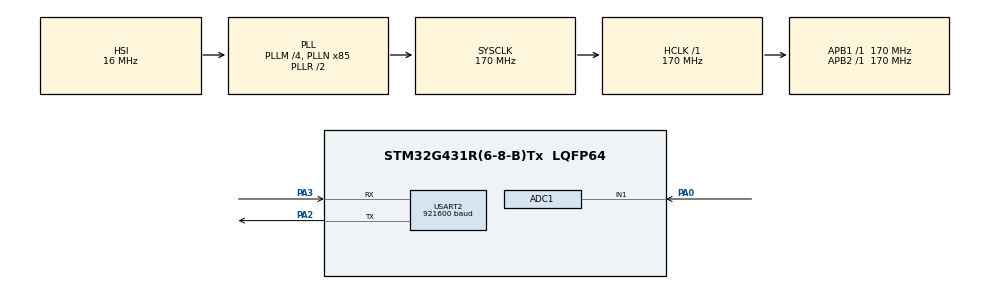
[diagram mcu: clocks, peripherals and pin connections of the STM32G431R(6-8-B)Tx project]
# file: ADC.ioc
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ADC1.Channel-0\#ChannelRegularConversion=ADC_CHANNEL_1
ADC1.ExternalTrigConv=ADC_EXTERNALTRIG_T2_TRGO
ADC1.NbrOfConversionFlag=1
ADC1.OffsetNumber-0\#ChannelRegularConversion=ADC_OFFSET_NONE
ADC1.Overrun=ADC_OVR_DATA_OVERWRITTEN
ADC1.Rank-0\#ChannelRegularConversion=1
ADC1.SamplingTime-0\#ChannelRegularConversion=ADC_SAMPLETIME_47CYCLES_5
ADC1.master=1
Dma.ADC1.1.Direction=DMA_PERIPH_TO_MEMORY
Dma.ADC1.1.EventEnable=DISABLE
Dma.ADC1.1.Instance=DMA1_Channel2
Dma.ADC1.1.MemDataAlignment=DMA_MDATAALIGN_HALFWORD
Dma.ADC1.1.MemInc=DMA_MINC_ENABLE
Dma.ADC1.1.Mode=DMA_CIRCULAR
Dma.ADC1.1.PeriphDataAlignment=DMA_PDATAALIGN_HALFWORD
Dma.ADC1.1.PeriphInc=DMA_PINC_DISABLE
Dma.ADC1.1.Polarity=HAL_DMAMUX_REQ_GEN_RISING
Dma.ADC1.1.Priority=DMA_PRIORITY_LOW
Dma.ADC1.1.RequestNumber=1
Dma.ADC1.1.SignalID=NONE
Dma.ADC1.1.SyncEnable=DISABLE
Dma.ADC1.1.SyncPolarity=HAL_DMAMUX_SYNC_NO_EVENT
Dma.ADC1.1.SyncRequestNumber=1
Dma.ADC1.1.SyncSignalID=NONE
Dma.Request0=USART2_TX
Dma.Request1=ADC1
Dma.USART2_TX.0.Direction=DMA_MEMORY_TO_PERIPH
Dma.USART2_TX.0.EventEnable=DISABLE
Dma.USART2_TX.0.Instance=DMA1_Channel1
Dma.USART2_TX.0.MemDataAlignment=DMA_MDATAALIGN_BYTE
Dma.USART2_TX.0.MemInc=DMA_MINC_ENABLE
Dma.USART2_TX.0.Mode=DMA_NORMAL
Dma.USART2_TX.0.PeriphDataAlignment=DMA_PDATAALIGN_BYTE
Dma.USART2_TX.0.PeriphInc=DMA_PINC_DISABLE
Dma.USART2_TX.0.Polarity=HAL_DMAMUX_REQ_GEN_RISING
Dma.USART2_TX.0.Priority=DMA_PRIORITY_LOW
Dma.USART2_TX.0.RequestNumber=1
Dma.USART2_TX.0.SignalID=NONE
Dma.USART2_TX.0.SyncEnable=DISABLE
Dma.USART2_TX.0.SyncPolarity=HAL_DMAMUX_SYNC_NO_EVENT
Dma.USART2_TX.0.SyncRequestNumber=1
Dma.USART2_TX.0.SyncSignalID=NONE
Mcu.Family=STM32G4
Mcu.Name=STM32G431R(6-8-B)Tx
Mcu.Package=LQFP64
NVIC.ADC1_2_IRQn=true\:0\:0\:false\:false\:true\:true\:true\:true
NVIC.DMA1_Channel1_IRQn=true\:0\:0\:false\:false\:true\:false\:true\:true
NVIC.DMA1_Channel2_IRQn=true\:0\:0\:false\:false\:true\:false\:true\:true
NVIC.PriorityGroup=NVIC_PRIORITYGROUP_4
PA0.Mode=IN1-Single-Ended
PA0.Signal=ADC1_IN1
PA13.GPIO_Label=T_SWDIO
PA13.Mode=Serial_Wire
PA13.Signal=SYS_JTMS-SWDIO
PA14.GPIO_Label=T_SWCLK
PA14.Mode=Serial_Wire
PA14.Signal=SYS_JTCK-SWCLK
PA2.Mode=Asynchronous
PA2.Signal=USART2_TX
PA3.Mode=Asynchronous
PA3.Signal=USART2_RX
PB3.GPIO_Label=T_SWO
PB3.Signal=SYS_JTDO-SWO
PC14-OSC32_IN.GPIO_Label=RCC_OSC32_OUT
PC14-OSC32_IN.Signal=RCC_OSC32_IN
PC15-OSC32_OUT.GPIO_Label=RCC_OSC32_OUT
PC15-OSC32_OUT.Signal=RCC_OSC32_OUT
PF0-OSC_IN.GPIO_Label=RCC_OSC_IN
PF0-OSC_IN.Signal=RCC_OSC_IN
PF1-OSC_OUT.GPIO_Label=RCC_OSC_OUT
PF1-OSC_OUT.Signal=RCC_OSC_OUT
ProjectManager.HeapSize=0x200
ProjectManager.StackSize=0x400
ProjectManager.TargetToolchain=CMake
RCC.ADC12Freq_Value=170000000
RCC.AHBFreq_Value=170000000
RCC.APB1Freq_Value=170000000
RCC.APB1TimFreq_Value=170000000
RCC.APB2Freq_Value=170000000
RCC.APB2TimFreq_Value=170000000
RCC.CortexFreq_Value=170000000
RCC.EXTERNAL_CLOCK_VALUE=12288000
RCC.HCLKFreq_Value=170000000
RCC.HSE_VALUE=24000000
RCC.HSI48_VALUE=48000000
RCC.HSI_VALUE=16000000
RCC.LSE_VALUE=32768
RCC.PLLM=RCC_PLLM_DIV4
RCC.PLLN=85
RCC.RTCClockSelection=RCC_RTCCLKSOURCE_LSE
RCC.SYSCLKFreq_VALUE=170000000
RCC.SYSCLKSource=RCC_SYSCLKSOURCE_PLLCLK
RCC.USBFreq_Value=170000000
RCC.VCOOutputFreq_Value=340000000
TIM2.PeriodNoDither=999
TIM2.Prescaler=169
TIM2.TIM_MasterOutputTrigger=TIM_TRGO_UPDATE
USART2.BaudRate=921600
USART2.VirtualMode-Asynchronous=VM_ASYNC
VP_SYS_VS_DBSignals.Mode=DisableDeadBatterySignals
VP_TIM2_VS_ClockSourceINT.Mode=Internal
board=NUCLEO-G431RB

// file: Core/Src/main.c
/* USER CODE BEGIN Header */
/**
  ******************************************************************************
  * @file           : main.c
  * @brief          : Main program body
  ******************************************************************************
  */
/* USER CODE END Header */
#include "main.h"

/* USER CODE BEGIN Includes */
#include <stdio.h>
/* USER CODE END Includes */

ADC_HandleTypeDef hadc1;
DMA_HandleTypeDef hdma_adc1;

UART_HandleTypeDef huart2;
DMA_HandleTypeDef hdma_usart2_tx;

TIM_HandleTypeDef htim2;

/* USER CODE BEGIN PV */
#define ADC_BUF_SIZE 2000
#define HALF_BUF_SIZE (ADC_BUF_SIZE / 2)

uint16_t adc_buffer[ADC_BUF_SIZE];
volatile uint8_t data_ready_flag = 0;
/* USER CODE END PV */

void SystemClock_Config(void);
static void MX_GPIO_Init(void);
static void MX_DMA_Init(void);
static void MX_USART2_UART_Init(void);
static void MX_ADC1_Init(void);
static void MX_TIM2_Init(void);

int main(void)
{

  /* MCU Configuration--------------------------------------------------------*/
  HAL_Init();

  /* Configure the system clock */
  SystemClock_Config();

  /* Initialize all configured peripherals */
  MX_GPIO_Init();
  MX_DMA_Init();          // Инициализация DMA строго ПЕРЕД АЦП и UART!
  MX_USART2_UART_Init();
  MX_ADC1_Init();
  MX_TIM2_Init();

  /* USER CODE BEGIN 2 */
  // 1. Запуск АЦП в циклическом режиме DMA на весь размер буфера
  HAL_ADC_Start_DMA(&hadc1, (uint32_t*)adc_buffer, ADC_BUF_SIZE);

  // 2. Запуск таймера TIM2, который аппаратно пинает АЦП с частотой 1 кГц
  HAL_TIM_Base_Start(&htim2);
  /* USER CODE END 2 */

  /* INFINITE LOOP */
  while (1)
  {

        /* USER CODE BEGIN 3 */
    if (data_ready_flag != 0)
    {
      uint8_t *tx_ptr;

      if (data_ready_flag == 1)
      {
        tx_ptr = (uint8_t*)&adc_buffer;
      }
      else
      {
        tx_ptr = (uint8_t*)&adc_buffer[HALF_BUF_SIZE];
      }

      // Сбрасываем флаг прерывания АЦП
      data_ready_flag = 0;

      // Ждём, пока UART ФИЗИЧЕСКИ не завершит передачу прошлых байт.
      // (USART_ISR_TC) — это железный флаг самого кремниевого кристалла.
      // Пока он равен 0, передатчик аппаратно занят.
      while ((huart2.Instance->ISR & USART_ISR_TC) == 0)
      {
        // Защитный таймаут на случай непредвиденного сбоя на линии
        if (huart2.ErrorCode != HAL_UART_ERROR_NONE) {
            HAL_UART_AbortTransmit(&huart2);
            break;
        }
      }

      // Принудительно возвращаем внутренний программный статус HAL в READY,
      // чтобы библиотека не паниковала и разрешила запуск DMA
      huart2.gState = HAL_UART_STATE_READY;

      // Запускаем аппаратный DMA USART2 на отправку пачки байт
      HAL_UART_Transmit_DMA(&huart2, tx_ptr, HALF_BUF_SIZE * 2);
    }
    /* USER CODE END 3 */

  }
}

void SystemClock_Config(void)
{
  RCC_OscInitTypeDef RCC_OscInitStruct = {0};
  RCC_ClkInitTypeDef RCC_ClkInitStruct = {0};

  HAL_PWREx_ControlVoltageScaling(PWR_REGULATOR_VOLTAGE_SCALE1_BOOST);

  RCC_OscInitStruct.OscillatorType = RCC_OSCILLATORTYPE_HSI;
  RCC_OscInitStruct.HSIState = RCC_HSI_ON;
  RCC_OscInitStruct.HSICalibrationValue = RCC_HSICALIBRATION_DEFAULT;
  RCC_OscInitStruct.PLL.PLLState = RCC_PLL_ON;
  RCC_OscInitStruct.PLL.PLLSource = RCC_PLLSOURCE_HSI;
  RCC_OscInitStruct.PLL.PLLM = RCC_PLLM_DIV4;
  RCC_OscInitStruct.PLL.PLLN = 85;
  RCC_OscInitStruct.PLL.PLLP = RCC_PLLP_DIV2;
  RCC_OscInitStruct.PLL.PLLQ = RCC_PLLQ_DIV2;
  RCC_OscInitStruct.PLL.PLLR = RCC_PLLR_DIV2;
  if (HAL_RCC_OscConfig(&RCC_OscInitStruct) != HAL_OK)
  {
    Error_Handler();
  }

  RCC_ClkInitStruct.ClockType = RCC_CLOCKTYPE_HCLK|RCC_CLOCKTYPE_SYSCLK

                              |RCC_CLOCKTYPE_PCLK1|RCC_CLOCKTYPE_PCLK2;
  RCC_ClkInitStruct.SYSCLKSource = RCC_SYSCLKSOURCE_PLLCLK;
  RCC_ClkInitStruct.AHBCLKDivider = RCC_SYSCLK_DIV1;
  RCC_ClkInitStruct.APB1CLKDivider = RCC_HCLK_DIV1;
  RCC_ClkInitStruct.APB2CLKDivider = RCC_HCLK_DIV1;

  if (HAL_RCC_ClockConfig(&RCC_ClkInitStruct, FLASH_LATENCY_4) != HAL_OK)
  {
    Error_Handler();
  }
}

static void MX_ADC1_Init(void)
{
  ADC_MultiModeTypeDef multimode = {0};
  ADC_ChannelConfTypeDef sConfig = {0};

  hadc1.Instance = ADC1;
  hadc1.Init.ClockPrescaler = ADC_CLOCK_SYNC_PCLK_DIV4;
  hadc1.Init.Resolution = ADC_RESOLUTION_12B;
  hadc1.Init.DataAlign = ADC_DATAALIGN_RIGHT;
  hadc1.Init.GainCompensation = 0;
  hadc1.Init.ScanConvMode = ADC_SCAN_DISABLE;
  hadc1.Init.EOCSelection = ADC_EOC_SINGLE_CONV;
  hadc1.Init.LowPowerAutoWait = DISABLE;
  hadc1.Init.ContinuousConvMode = DISABLE;
  hadc1.Init.NbrOfConversion = 1;
  hadc1.Init.DiscontinuousConvMode = DISABLE;
  hadc1.Init.ExternalTrigConv = ADC_EXTERNALTRIG_T2_TRGO;
  hadc1.Init.ExternalTrigConvEdge = ADC_EXTERNALTRIGCONVEDGE_RISING;
  hadc1.Init.DMAContinuousRequests = ENABLE;    // Прямой непрерывный перезапуск
  hadc1.Init.Overrun = ADC_OVR_DATA_OVERWRITTEN; // Автоперезапись при оверране
  hadc1.Init.OversamplingMode = DISABLE;
  if (HAL_ADC_Init(&hadc1) != HAL_OK)
  {
    Error_Handler();
  }

  multimode.Mode = ADC_MODE_INDEPENDENT;
  if (HAL_ADCEx_MultiModeConfigChannel(&hadc1, &multimode) != HAL_OK)
  {
    Error_Handler();
  }

  sConfig.Channel = ADC_CHANNEL_1;
  sConfig.Rank = ADC_REGULAR_RANK_1;
  sConfig.SamplingTime = ADC_SAMPLETIME_47CYCLES_5; // Высокая точность
  sConfig.SingleDiff = ADC_SINGLE_ENDED;
  sConfig.OffsetNumber = ADC_OFFSET_NONE;
  sConfig.Offset = 0;
  if (HAL_ADC_ConfigChannel(&hadc1, &sConfig) != HAL_OK)
  {
    Error_Handler();
  }
}

static void MX_USART2_UART_Init(void)
{
  huart2.Instance = USART2;
  huart2.Init.BaudRate = 921600;
  huart2.Init.WordLength = UART_WORDLENGTH_8B;
  huart2.Init.StopBits = UART_STOPBITS_1;
  huart2.Init.Parity = UART_PARITY_NONE;
  huart2.Init.Mode = UART_MODE_TX_RX;
  huart2.Init.HwFlowCtl = UART_HWCONTROL_NONE;
  huart2.Init.OverSampling = UART_OVERSAMPLING_16;
  huart2.Init.OneBitSampling = UART_ONE_BIT_SAMPLE_DISABLE;
  huart2.AdvancedInit.AdvFeatureInit = UART_ADVFEATURE_NO_INIT;
  if (HAL_UART_Init(&huart2) != HAL_OK)
  {
    Error_Handler();
  }
}

static void MX_TIM2_Init(void)
{
  TIM_ClockConfigTypeDef sClockSourceConfig = {0};
  TIM_MasterConfigTypeDef sMasterConfig = {0};

  htim2.Instance = TIM2;
  htim2.Init.Prescaler = 169;
  htim2.Init.CounterMode = TIM_COUNTERMODE_UP;
  htim2.Init.Period = 999;
  htim2.Init.ClockDivision = TIM_CLOCKDIVISION_DIV1;
  htim2.Init.AutoReloadPreload = TIM_AUTORELOAD_PRELOAD_DISABLE;
  if (HAL_TIM_Base_Init(&htim2) != HAL_OK)
  {
    Error_Handler();
  }
  sClockSourceConfig.ClockSource = TIM_CLOCKSOURCE_INTERNAL;
  if (HAL_TIM_ConfigClockSource(&htim2, &sClockSourceConfig) != HAL_OK)
  {
    Error_Handler();
  }
  sMasterConfig.MasterOutputTrigger = TIM_TRGO_UPDATE; // Ровно 1 кГц
  sMasterConfig.MasterSlaveMode = TIM_MASTERSLAVEMODE_DISABLE;
  if (HAL_TIMEx_MasterConfigSynchronization(&htim2, &sMasterConfig) != HAL_OK)
  {
    Error_Handler();
  }
}

static void MX_DMA_Init(void)
{
  /* DMA controller clock enable */
  __HAL_RCC_DMAMUX1_CLK_ENABLE();
  __HAL_RCC_DMA1_CLK_ENABLE();

  /* DMA interrupt init */
  HAL_NVIC_SetPriority(DMA1_Channel1_IRQn, 0, 0);
  HAL_NVIC_EnableIRQ(DMA1_Channel1_IRQn);
  HAL_NVIC_SetPriority(DMA1_Channel2_IRQn, 0, 0);
  HAL_NVIC_EnableIRQ(DMA1_Channel2_IRQn);
}

static void MX_GPIO_Init(void)
{
  __HAL_RCC_GPIOA_CLK_ENABLE();
}

/* USER CODE BEGIN 4 */
void HAL_ADC_ConvHalfCpltCallback(ADC_HandleTypeDef* hadc)
{
  if (hadc->Instance == ADC1)
  {
    data_ready_flag = 1;
    __HAL_UART_CLEAR_FLAG(&huart2, UART_CLEAR_OREF);
  }
}

void HAL_ADC_ConvCpltCallback(ADC_HandleTypeDef* hadc)
{
  if (hadc->Instance == ADC1)
  {
    data_ready_flag = 2;
    __HAL_UART_CLEAR_FLAG(&huart2, UART_CLEAR_OREF);
  }
}

void Error_Handler(void)
{
  __disable_irq();
  while (1)
  {
  }
}
/* USER CODE END 4 */
